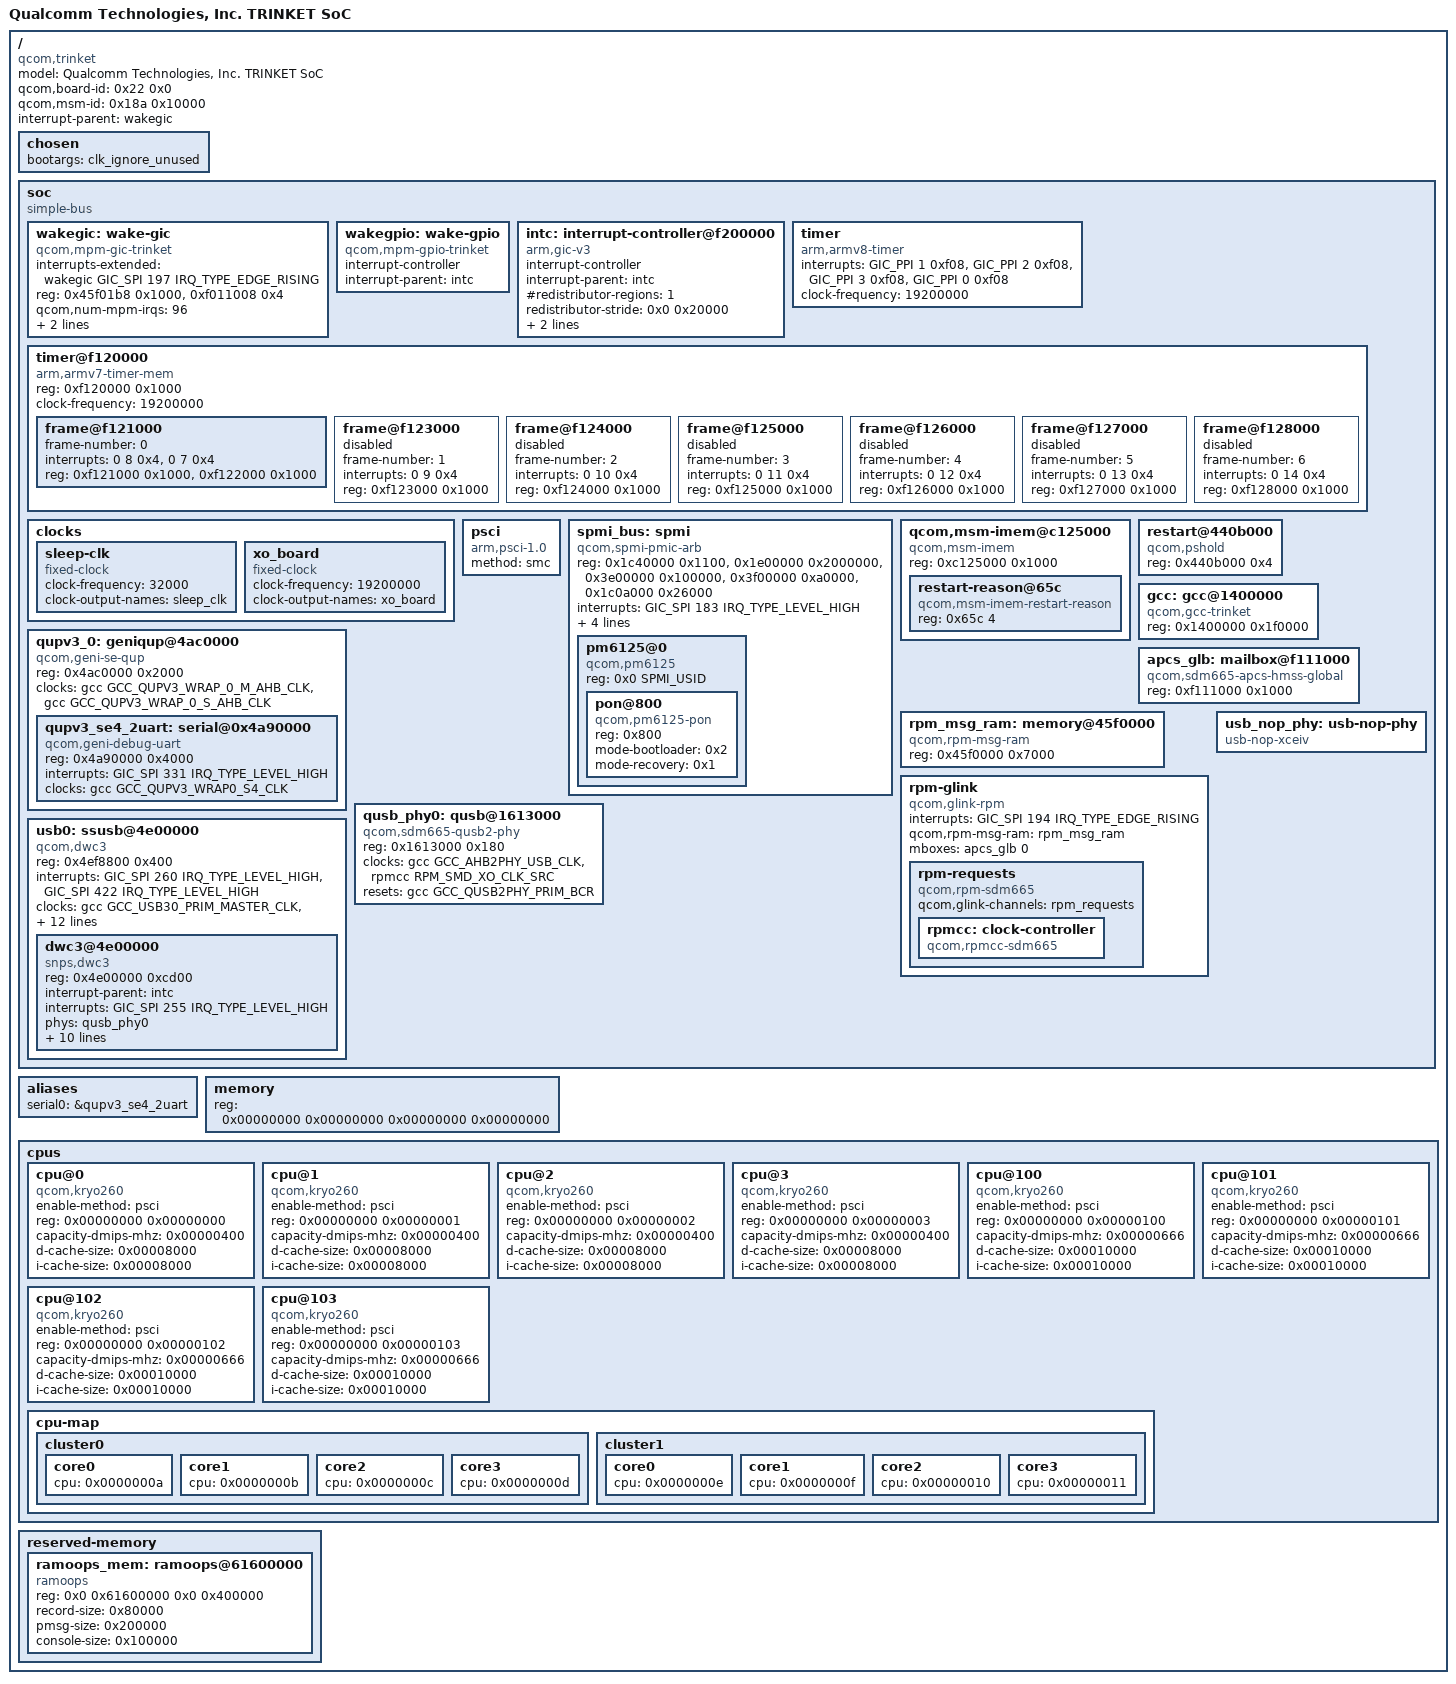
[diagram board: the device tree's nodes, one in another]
/dts-v1/;
// version:		17
// last_comp_version:	16
// boot_cpuid_phys:	0x0

#include <dt-bindings/interrupt-controller/arm-gic.h>
#include <dt-bindings/clock/qcom,gcc-trinket.h>
#include <dt-bindings/clock/qcom,rpmcc.h>
#include <dt-bindings/spmi/spmi.h>

/ {
    model = "Qualcomm Technologies, Inc. TRINKET SoC";
    compatible = "qcom,trinket";
    #address-cells = <0x00000002>;
    #size-cells = <0x00000002>;
    qcom,board-id = <0x22 0x0>;
    qcom,msm-id = <0x18a 0x10000>;
    interrupt-parent = <&wakegic>;
    chosen {
        bootargs = "clk_ignore_unused";
    };
    soc: soc { };
    aliases {
        serial0 = &qupv3_se4_2uart;
    };
    memory {
        device_type = "memory";
        reg = <0x00000000 0x00000000 0x00000000 0x00000000>;
    };
    cpus {
        #address-cells = <0x00000002>;
        #size-cells = <0x00000000>;
        cpu@0 {
            device_type = "cpu";
            enable-method = "psci";
            reg = <0x00000000 0x00000000>;
            capacity-dmips-mhz = <0x00000400>;
            d-cache-size = <0x00008000>;
            i-cache-size = <0x00008000>;
            phandle = <0x0000000a>;
            compatible = "qcom,kryo260";
        };
        cpu@1 {
            device_type = "cpu";
            enable-method = "psci";
            reg = <0x00000000 0x00000001>;
            capacity-dmips-mhz = <0x00000400>;
            d-cache-size = <0x00008000>;
            i-cache-size = <0x00008000>;
            phandle = <0x0000000b>;
            compatible = "qcom,kryo260";
        };
        cpu@2 {
            device_type = "cpu";
            enable-method = "psci";
            reg = <0x00000000 0x00000002>;
            capacity-dmips-mhz = <0x00000400>;
            d-cache-size = <0x00008000>;
            i-cache-size = <0x00008000>;
            phandle = <0x0000000c>;
            compatible = "qcom,kryo260";
        };
        cpu@3 {
            device_type = "cpu";
            enable-method = "psci";
            reg = <0x00000000 0x00000003>;
            capacity-dmips-mhz = <0x00000400>;
            d-cache-size = <0x00008000>;
            i-cache-size = <0x00008000>;
            phandle = <0x0000000d>;
            compatible = "qcom,kryo260";
        };
        cpu@100 {
            device_type = "cpu";
            enable-method = "psci";
            reg = <0x00000000 0x00000100>;
            capacity-dmips-mhz = <0x00000666>;
            d-cache-size = <0x00010000>;
            i-cache-size = <0x00010000>;
            phandle = <0x0000000e>;
            compatible = "qcom,kryo260";
        };
        cpu@101 {
            device_type = "cpu";
            enable-method = "psci";
            reg = <0x00000000 0x00000101>;
            capacity-dmips-mhz = <0x00000666>;
            d-cache-size = <0x00010000>;
            i-cache-size = <0x00010000>;
            phandle = <0x0000000f>;
            compatible = "qcom,kryo260";
        };
        cpu@102 {
            device_type = "cpu";
            enable-method = "psci";
            reg = <0x00000000 0x00000102>;
            capacity-dmips-mhz = <0x00000666>;
            d-cache-size = <0x00010000>;
            i-cache-size = <0x00010000>;
            phandle = <0x00000010>;
            compatible = "qcom,kryo260";
        };
        cpu@103 {
            device_type = "cpu";
            enable-method = "psci";
            reg = <0x00000000 0x00000103>;
            capacity-dmips-mhz = <0x00000666>;
            d-cache-size = <0x00010000>;
            i-cache-size = <0x00010000>;
            phandle = <0x00000011>;
            compatible = "qcom,kryo260";
        };
        cpu-map {
            cluster0 {
                core0 {
                    cpu = <0x0000000a>;
                };
                core1 {
                    cpu = <0x0000000b>;
                };
                core2 {
                    cpu = <0x0000000c>;
                };
                core3 {
                    cpu = <0x0000000d>;
                };
            };
            cluster1 {
                core0 {
                    cpu = <0x0000000e>;
                };
                core1 {
                    cpu = <0x0000000f>;
                };
                core2 {
                    cpu = <0x00000010>;
                };
                core3 {
                    cpu = <0x00000011>;
                };
            };
        };
    };
    reserved-memory {
        #address-cells = <2>;
        #size-cells = <2>;
        ranges;
        ramoops_mem: ramoops@61600000 {
            compatible = "ramoops";
            reg = <0x0 0x61600000 0x0 0x400000>;
            record-size = <0x80000>;
            pmsg-size = <0x200000>;
            console-size = <0x100000>;
        };
    };
};

&soc {
    #address-cells = <1>;
    #size-cells = <1>;
    ranges = <0 0 0 0xffffffff>;
    compatible = "simple-bus";

    wakegic: wake-gic {
        compatible = "qcom,mpm-gic-trinket", "qcom,mpm-gic";
        interrupts-extended = <&wakegic GIC_SPI 197 IRQ_TYPE_EDGE_RISING>;
        reg = <0x45f01b8 0x1000>, <0xf011008 0x4>;  // MSM_APCS_GCC_BASE 4K
        reg-names = "vmpm", "ipc";
        qcom,num-mpm-irqs = <96>;
        interrupt-controller;
        interrupt-parent = <&intc>;
        #interrupt-cells = <3>;
    };

    wakegpio: wake-gpio {
        compatible = "qcom,mpm-gpio-trinket", "qcom,mpm-gpio";
        interrupt-controller;
        interrupt-parent = <&intc>;
        #interrupt-cells = <2>;
    };

    intc: interrupt-controller@f200000 {
        compatible = "arm,gic-v3";
        #interrupt-cells = <3>;
        interrupt-controller;
        interrupt-parent = <&intc>;
        #redistributor-regions = <1>;
        redistributor-stride = <0x0 0x20000>;
        reg = <0xf200000 0x10000>,     
              <0xf300000 0x100000>;   /* GICD, GICR * 8 */
        interrupts = <GIC_PPI 9 4>;
    };

    timer {
        compatible = "arm,armv8-timer";
        interrupts = <GIC_PPI 1 0xf08>,
                 <GIC_PPI 2 0xf08>,
                 <GIC_PPI 3 0xf08>,
                 <GIC_PPI 0 0xf08>;
        clock-frequency = <19200000>;
    };

    timer@f120000 {
        #address-cells = <1>;
        #size-cells = <1>;
        ranges;
        compatible = "arm,armv7-timer-mem";
        reg = <0xf120000 0x1000>;
        clock-frequency = <19200000>;

        frame@f121000 {
            frame-number = <0>;
            interrupts = <0 8 0x4>,
                     <0 7 0x4>;
            reg = <0xf121000 0x1000>,
                  <0xf122000 0x1000>;
        };

        frame@f123000 {
            frame-number = <1>;
            interrupts = <0 9 0x4>;
            reg = <0xf123000 0x1000>;
            status = "disabled";
        };

        frame@f124000 {
            frame-number = <2>;
            interrupts = <0 10 0x4>;
            reg = <0xf124000 0x1000>;
            status = "disabled";
        };

        frame@f125000 {
            frame-number = <3>;
            interrupts = <0 11 0x4>;
            reg = <0xf125000 0x1000>;
            status = "disabled";
        };

        frame@f126000 {
            frame-number = <4>;
            interrupts = <0 12 0x4>;
            reg = <0xf126000 0x1000>;
            status = "disabled";
        };

        frame@f127000 {
            frame-number = <5>;
            interrupts = <0 13 0x4>;
            reg = <0xf127000 0x1000>;
            status = "disabled";
        };

        frame@f128000 {
            frame-number = <6>;
            interrupts = <0 14 0x4>;
            reg = <0xf128000 0x1000>;
            status = "disabled";
        };
    };

    clocks {
        sleep-clk {
            compatible = "fixed-clock";
            clock-frequency = <32000>;
            clock-output-names = "sleep_clk";
            #clock-cells = <1>;
        };

        xo_board {
            compatible = "fixed-clock";
            #clock-cells = <0>;
            clock-frequency = <19200000>;
            clock-output-names = "xo_board";
        };
    };

    psci {
        compatible = "arm,psci-1.0";
        method = "smc";
    };

    spmi_bus: spmi {
        compatible = "qcom,spmi-pmic-arb";
        reg-names = "core", "chnls", "obsrvr", "intr", "cnfg";
        reg = <0x1c40000 0x1100>,
              <0x1e00000 0x2000000>,
              <0x3e00000 0x100000>,
              <0x3f00000 0xa0000>,
              <0x1c0a000 0x26000>;
        interrupt-names = "periph_irq";
        interrupts = <GIC_SPI 183 IRQ_TYPE_LEVEL_HIGH>;
        qcom,ee = <0>;
        qcom,channel = <0>;
        #address-cells = <2>;
        #size-cells = <0>;
        interrupt-controller;
        #interrupt-cells = <4>;
        cell-index = <0>;
    };

    qcom,msm-imem@c125000 {
        compatible = "qcom,msm-imem";
        reg = <0xc125000 0x1000>;
        ranges = <0x0 0xc125000 0x1000>;
        #address-cells = <1>;
        #size-cells = <1>;
        restart-reason@65c {
            compatible = "qcom,msm-imem-restart-reason";
            reg = <0x65c 4>;
        };
    };

    restart@440b000 {
        compatible = "qcom,pshold";
        /*
        reg = <0x440b000 0x4>, <0x03d3000 0x4>;
        reg-names = "pshold-base", "tcsr-boot-misc-detect";
        */
        reg = <0x440b000 0x4>;
    };

    gcc: gcc@1400000 {
        compatible = "qcom,gcc-trinket", "syscon";
        reg = <0x1400000 0x1f0000>;
        #clock-cells = <1>;
        #reset-cells = <1>;
        #power-domain-cells = <1>;
    };

    qupv3_0: geniqup@4ac0000 {
        compatible = "qcom,geni-se-qup";
        reg = <0x4ac0000 0x2000>;
        clock-names = "m-ahb", "s-ahb";
        clocks = <&gcc GCC_QUPV3_WRAP_0_M_AHB_CLK>, 
                 <&gcc GCC_QUPV3_WRAP_0_S_AHB_CLK>;
        #address-cells = <1>;
        #size-cells = <1>;
        ranges;

        qupv3_se4_2uart: serial@0x4a90000 {
            compatible = "qcom,geni-debug-uart";
            reg = <0x4a90000 0x4000>;
            interrupts = <GIC_SPI 331 IRQ_TYPE_LEVEL_HIGH>;
            clock-names = "se";
            clocks = <&gcc GCC_QUPV3_WRAP0_S4_CLK>;
        };
    };

    apcs_glb: mailbox@f111000 {
        compatible = "qcom,sdm665-apcs-hmss-global";
        reg = <0xf111000 0x1000>;
        #mbox-cells = <1>;
    };

    rpm_msg_ram: memory@45f0000 {
        compatible = "qcom,rpm-msg-ram";
        reg = <0x45f0000 0x7000>;
    };

    rpm-glink {
        compatible = "qcom,glink-rpm";
        interrupts = <GIC_SPI 194 IRQ_TYPE_EDGE_RISING>;
        qcom,rpm-msg-ram = <&rpm_msg_ram>;
        mboxes = <&apcs_glb 0>;
        rpm-requests {
            compatible = "qcom,rpm-sdm665";
            qcom,glink-channels = "rpm_requests";
            rpmcc: clock-controller {
                compatible = "qcom,rpmcc-sdm665", "qcom,rpmcc";
                #clock-cells = <1>;
            };
        };
    };

    // usb HS phy
    qusb_phy0: qusb@1613000 {
        compatible = "qcom,sdm665-qusb2-phy";
        reg = <0x1613000 0x180>;
        #phy-cells = <0>;

        clock-names = "cfg_ahb", "ref";
        clocks = <&gcc GCC_AHB2PHY_USB_CLK>, <&rpmcc RPM_SMD_XO_CLK_SRC>;

        // vdda-pll-supply = <&dummy>;
        // vdda-phy-dpdm-supply = <&dummy>;

        resets = <&gcc GCC_QUSB2PHY_PRIM_BCR>;
    };

    // usb SS nop phy
    usb_nop_phy: usb-nop-phy {
        compatible = "usb-nop-xceiv";
    };

    usb0: ssusb@4e00000 {
        compatible = "qcom,dwc3";
        reg = <0x4ef8800 0x400>;
        #address-cells = <1>;
        #size-cells = <1>;
        ranges;

        interrupt-names = "hs_phy_irq", "ss_phy_irq";
        interrupts = <GIC_SPI 260 IRQ_TYPE_LEVEL_HIGH>, <GIC_SPI 422 IRQ_TYPE_LEVEL_HIGH>;

        clock-names = "core", "mock_utmi", "sleep", "xo", "iface", "bus_aggr";
        clocks = <&gcc GCC_USB30_PRIM_MASTER_CLK>,
                 <&gcc GCC_USB30_PRIM_MOCK_UTMI_CLK>,
                 <&gcc GCC_USB30_PRIM_SLEEP_CLK>,
                 <&gcc GCC_SYS_NOC_USB3_PRIM_AXI_CLK>,
                 <&gcc GCC_CFG_NOC_USB3_PRIM_AXI_CLK>,
                 <&gcc GCC_USB3_PRIM_CLKREF_CLK>;

        assigned-clocks = <&gcc GCC_USB30_PRIM_MOCK_UTMI_CLK>,
                          <&gcc GCC_USB30_PRIM_MASTER_CLK>;
        assigned-clock-rates = <19200000>, <66666667>;

        reset-names = "core_reset";
        resets = <&gcc GCC_USB30_PRIM_BCR>;
        power-domains = <&gcc USB30_PRIM_GDSC>;

        qcom,select-utmi-as-pipe-clk;

        dwc3@4e00000 {
            compatible = "snps,dwc3";
            reg = <0x4e00000 0xcd00>;
            interrupt-parent = <&intc>;
            interrupts = <GIC_SPI 255 IRQ_TYPE_LEVEL_HIGH>;
            phys = <&qusb_phy0>;
            phy-names = "usb2-phy";
            tx-fifo-resize;
            linux,sysdev_is_parent;
            snps,disable-clk-gating;
            snps,dis_u2_susphy_quirk;
            snps,dis_enblslpm_quirk;
            snps,has-lpm-erratum;
            snps,hird-threshold = /bits/ 8 <0x10>;
            snps,usb3_lpm_capable;
            maximum-speed = "high-speed";
            dr_mode = "peripheral";
        };
    };
};

&spmi_bus {
    pm6125@0 {
        compatible = "qcom,pm6125", "qcom,spmi-pmic";
        reg = <0x0 SPMI_USID>;
        #address-cells = <1>;
        #size-cells = <0>;

        pon@800 {
            compatible = "qcom,pm6125-pon";
            reg = <0x800>;
            mode-bootloader = <0x2>;
            mode-recovery = <0x1>;

            /*
            pwrkey {
                compatible = "qcom,pm6125-pwrkey";
                // TODO: fix
                interrupts = <0x0 0x8 0 IRQ_TYPE_EDGE_BOTH>;
                debounce = <15625>;
                bias-pull-up;
                linux,code = <KEY_POWER>;
            };

            watchdog {
                compatible = "qcom,pm6125-wdt";
                // TODO: fix
                interrupts = <0x0 0x8 6 IRQ_TYPE_EDGE_RISING>;
                timeout-sec = <60>;
            };
            */
        };

    };
};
